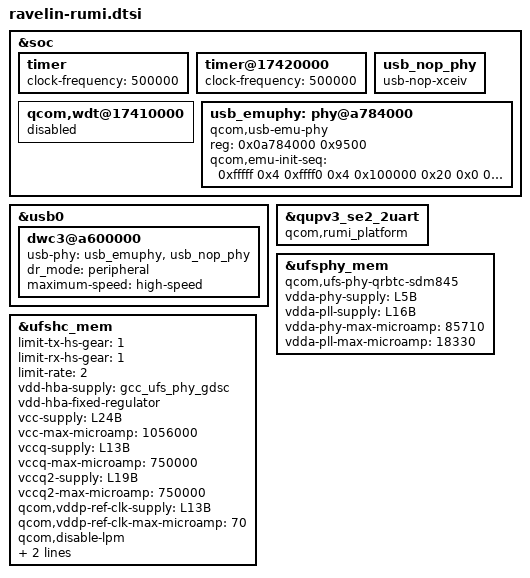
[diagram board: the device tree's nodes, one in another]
&soc {
	timer {
		clock-frequency = <500000>;
	};

	timer@17420000 {
		clock-frequency = <500000>;
	};

	qcom,wdt@17410000 {
		status = "disabled";
	};

	usb_nop_phy: usb_nop_phy {
		compatible = "usb-nop-xceiv";
	};

	usb_emuphy: phy@a784000 {
		compatible = "qcom,usb-emu-phy";
		reg = <0x0a784000 0x9500>;

		qcom,emu-init-seq = <0xfffff 0x4
			0xffff0 0x4
			0x100000 0x20
			0x0 0x20
			0x000001A0 0x20
			0x00100000 0x3c
			0x0 0x3c
			0x0 0x4>;
		};
};

&usb0 {
	dwc3@a600000 {
		usb-phy = <&usb_emuphy>, <&usb_nop_phy>;
		dr_mode = "peripheral";
		maximum-speed = "high-speed";
	};


};

&qupv3_se2_2uart {
	qcom,rumi_platform;
};

&ufsphy_mem {
	compatible = "qcom,ufs-phy-qrbtc-sdm845";

	vdda-phy-supply = <&L5B>;
	vdda-pll-supply = <&L16B>;
	vdda-phy-max-microamp = <85710>;
	vdda-pll-max-microamp = <18330>;

	status = "ok";
};

&ufshc_mem {
	limit-tx-hs-gear = <1>;
	limit-rx-hs-gear = <1>;
	limit-rate = <2>; /* HS Rate-B */

	vdd-hba-supply = <&gcc_ufs_phy_gdsc>;
	vdd-hba-fixed-regulator;

	vcc-supply = <&L24B>;
	vcc-max-microamp = <1056000>;

	vccq-supply = <&L13B>;
	vccq-max-microamp = <750000>;

	vccq2-supply = <&L19B>;
	vccq2-max-microamp = <750000>;

	qcom,vddp-ref-clk-supply = <&L13B>;
	qcom,vddp-ref-clk-max-microamp = <70>;

	qcom,disable-lpm;
	rpm-level = <0>;
	spm-level = <0>;

	status = "ok";
};
